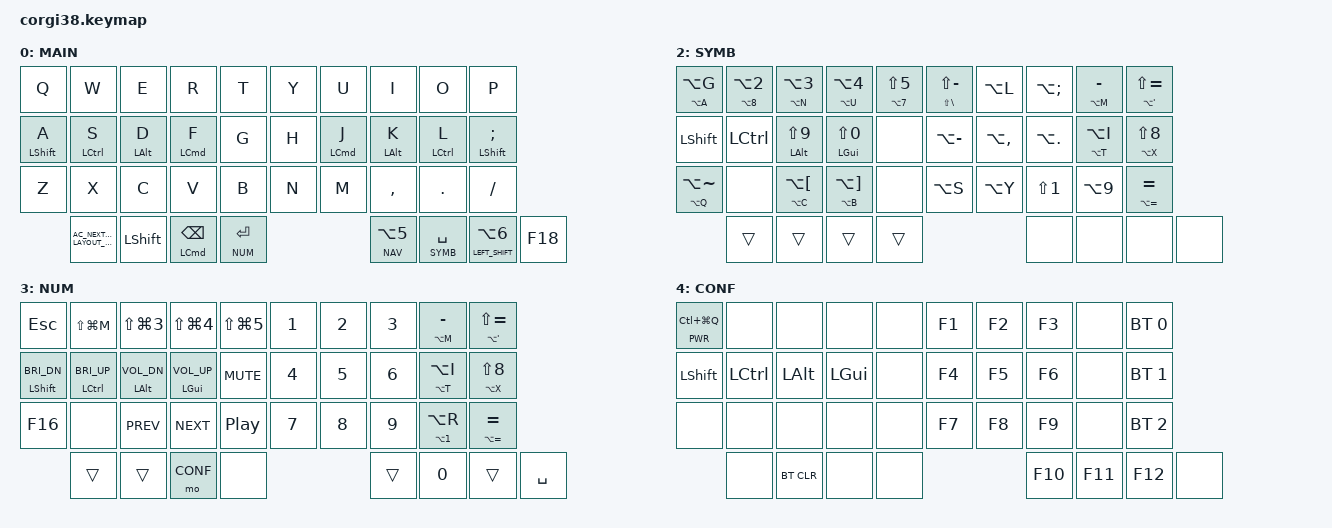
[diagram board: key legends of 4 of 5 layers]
// This keymap is designed for macOS

#include <behaviors.dtsi>
#include <dt-bindings/zmk/keys.h>
#include <dt-bindings/zmk/bt.h>

// LAYERS
#define MAIN  0
#define NAV   1
#define SYMB  2
#define NUM   3
#define CONF  4

#define WDL   &kp LA(BSPC)           //delete a word


&mt {
    tapping-term-ms = <200>;
};

/ {
  combos {
    compatible = "zmk,combos";

    //Caps Word Behavior, tap SW11 and SW20 at the same time
    combo_space {
    timeout-ms = <200>;
    key-positions = <32 33>;
    bindings = <&kp SPACE>;
        };

    //Tab Behavior, tap SW36 and SW37 at the same time
    combo_tab {
    timeout-ms = <200>;
    key-positions = <34 35>;
    bindings = <&kp TAB>;
        };

    //word delete Behavior, 
    combo_word_delete {
    timeout-ms = <150>;
    key-positions = <31 32>;
    bindings = <WDL>;
        };

    //combo_capslock {
    //timeout-ms = <150>;
    //key-positions = <10 19>;
    //bindings = <&caps_word>;
       // };

    //Change imput language, tap SW34 and SW35 at the same time
    combo_lang {
    timeout-ms = <300>;
    key-positions = <33 34>;
    bindings = <&lang>;
              };
    };

  behaviors {

  //macOS imput language shortcut: CMD+Space on Tap, Alt+Opt+Space on 2 taps (Tap-Dance Behavior) 
  lang: lang_lang {
    compatible = "zmk,behavior-tap-dance";
    #binding-cells = <0>;
    tapping-term-ms = <200>;
    bindings = <&kp LG(SPACE)>, <&kp LC(LA(SPACE))>;
        };      

  //Home Mods config for the MAIN layer  
  hm: hold_tap_mods {
    compatible = "zmk,behavior-hold-tap";
    #binding-cells = <2>;
    tapping_term_ms = <160>;
    require-prior-idle-ms = <125>;
    flavor = "tap-preferred";
    bindings = <&kp>, <&kp>;
};

  //Home Mods for shifts  
  sh: hold_tap_shifts {
    compatible = "zmk,behavior-hold-tap";
    #binding-cells = <2>;
    tapping_term_ms = <200>;
    flavor = "hold-preferred";
    bindings = <&kp>, <&kp>;
};

  //Hold-taps config for thumb claster (layer switching)
  hl: hold_tap_layers {
    compatible = "zmk,behavior-hold-tap";
    #binding-cells = <2>;
    tapping_term_ms = <180>;
    flavor = "hold-preferred";
    bindings = <&mo>, <&kp>;
};

  //Hold-taps config for thumb space
  sp: hold_tap_sp {
    compatible = "zmk,behavior-hold-tap";
    #binding-cells = <2>;
    tapping_term_ms = <130>;
    flavor = "hold-preferred";
    require-prior-idle-ms = <125>;
    bindings = <&mo>, <&kp>;
};

  };

    keymap {
        compatible = "zmk,keymap";

        // | SW1  | SW2  | SW3  | SW4  | SW5  |         | SW6  | SW7  | SW8  | SW9  | SW10 |
        // | SW11 | SW12 | SW13 | SW14 | SW15 |         | SW16 | SW17 | SW18 | SW19 | SW20 |
        // | SW21 | SW22 | SW23 | SW24 | SW25 |         | SW26 | SW27 | SW28 | SW29 | SW30 |
        //        | SW31 | SW32 | SW33 | SW34 |         | SW35 | SW36 | SW37 | SW38 |

        //MAIN Layer

        //Home Mods and letters for the LEFT half
        #define HM_A          &hm LEFT_SHIFT A           //SW11
        #define HM_S          &hm LEFT_CONTROL S         //SW12
        #define HM_D          &hm LEFT_ALT D             //SW13
        #define HM_F          &hm LCMD F                 //SW14
        
        //Home Mods for the RIGHT half 
        #define HM_J          &hm LCMD J                 //SW17
        #define HM_K          &hm LEFT_ALT K             //SW18
        #define HM_L          &hm LEFT_CONTROL L         //SW19
        #define HM_SEMI       &hm LEFT_SHIFT SEMI        //SW20
                                                         //SW30: &lang (macOS lang behavior)


        //Left Thumbs
        #define SPECE_SHIFT   &sh LEFT_SHIFT  SPACE      //SW31: ESC on Tap
                                                         //SW32: Space on Tap
        #define BSPC_CMD      &mt LCMD BSPC              //SW33: CMD on hold, Backspace on Tap
        #define NUM_ENTER     &hl NUM   ENTER            //SW34: NUMB layer on hold, ENTER on Tap

        //Right Thumbs
        #define NAV_COMMA     &hl NAV   LA(N5)           //SW35: NAV layer onf hold, COMMA on Tap
        #define SYMB_SPACE    &sp SYMB  SPACE            //SW36: Symbol layer on hold, Space on Tap
        #define MY_DOT        &sp LEFT_SHIFT   LA(N6)    //SW37: Custom DOT on tap
                                                         //F14 on Tap

        default_layer {
            display-name = "MAIN";
              bindings = <
                &kp Q       &kp W           &kp E          &kp R           &kp T                     &kp Y         &kp U         &kp I          &kp O         &kp P      
                HM_A        HM_S            HM_D           HM_F            &kp G                     &kp H         HM_J          HM_K           HM_L          HM_SEMI  
                &kp Z       &kp X           &kp C          &kp V           &kp B                     &kp N         &kp M         &kp COMMA      &kp DOT       &kp SLASH
                            &kp C_AC_NEXT_KEYBOARD_LAYOUT_SELECT       &kp LSHFT      BSPC_CMD        NUM_ENTER                 NAV_COMMA     SYMB_SPACE    MY_DOT         &kp F18 
                                  >;

                 };   

        //Nav layer
        // | SW1  | SW2  | SW3  | SW4  | SW5  |         | SW6  | SW7  | SW8  | SW9  | SW10 |
        // | SW11 | SW12 | SW13 | SW14 | SW15 |         | SW16 | SW17 | SW18 | SW19 | SW20 |
        // | SW21 | SW22 | SW23 | SW24 | SW25 |         | SW26 | SW27 | SW28 | SW29 | SW30 |
        //        | SW31 | SW32 | SW33 | SW34 |         | SW35 | SW36 | SW37 | SW38 |

        //RAW1
                                                          //SW1: &none 
                                                          //SW2: &none                                                  
                                                          //SW3: &none                                                      
                                                          //SW4: &none
        #define DRSS_E         &mt LS(GRAVE) GRAVE        //SW5: E with diaeresis (Ë), shifted on hold

        #define ZOOM_OUT       &kp LG(MINUS)              //SW6: CMD- shortcut 
        #define ZOOM_IN        &kp LG(EQUAL)              //SW7: CMD+ shortcut 
        #define ARROW_UP       &kp UP                     //SW8: arrow up
                                                          //SW9: &none 
        #define CYR_X          &mt LS(LBKT) LBKT          //SW10: Cyrillic x, and X on hold

        //RAW2
                                                          //SW11: LSHFT on tap
                                                          //SW12: LCTRL on tap 
                                                          //SW13: LALT on tap
                                                          //SW14: LGUI on tap
                                                          //SW15: &none 
 
                                                          //SW16: TAB on Tap 
        #define ARROW_LEFT     &kp LEFT                   //SW17: arrow left
        #define ARROW_DOWN     &kp DOWN                   //SW18: arrow down
        #define ARROW_RIGHT    &kp RIGHT                  //SW19: arrow right
        #define CYR_E          &mt LS(APOS) APOS          //SW20: Cyrillic э, and Э on hold


        //RAW3
                                                          //SW21: &none 
                                                          //SW22: &none                                                  
                                                          //SW23: &none                                                      
                                                          //SW24: &none
                                                          //SW25: &none

                                                          //SW26: &none
        #define CYR_HS         &mt LS(RBKT) RBKT          //SW27: Cyrillic ъ, and Ъ on hold (hard sign)
                                                          //SW28: &none                                                      
                                                          //SW29: &none
                                                          //SW30: &none
        #define S_QMARK         &mt LA(F) LA(N9)          //SW27: ? on tap, ¿ on hold 
        #define S_EXCLAM        &mt LA(D) LS(N1)          //SW28: ! on tap, ¡ on hold

        //Left Thumbs
                                                         //SW31: ESC on Tap
                                                         //SW32: Space on Tap
                                                         //SW33: CMD on hold, Backspace on Tap
                                                         //SW34: NUMB layer on hold, ENTER on Tap

        //Right Thumbs
                                                         //SW35: &none
                                                         //SW36: &none

        

        navigation_layer {
            display-name = "NAV";
              bindings = <
                &none          &none           &none          &none           DRSS_E                   ZOOM_OUT      ZOOM_IN         ARROW_UP        &none            CYR_X      
                &kp LSHFT      &kp LCTRL       &kp LALT       &kp LGUI        &kp F16                  &kp TAB       ARROW_LEFT      ARROW_DOWN      ARROW_RIGHT      CYR_E
                &none          &none           &none          &none           &none                    &none         &none           &none           &none
                               &trans          &trans         &trans          &trans                   &none         &none           &none           &none
                                  >; 
                      };


        //SYMB layer

        // | SW1  | SW2  | SW3  | SW4  | SW5  |         | SW6  | SW7  | SW8  | SW9  | SW10 |
        // | SW11 | SW12 | SW13 | SW14 | SW15 |         | SW16 | SW17 | SW18 | SW19 | SW20 |
        // | SW21 | SW22 | SW23 | SW24 | SW25 |         | SW26 | SW27 | SW28 | SW29 | SW30 |
        //        | SW31 | SW32 | SW33 | SW34 |         | SW35 | SW36 | SW37 | SW38 |

        //ROW 1      
        #define S_TILDE         &mt LA(A) LA(G)          //SW1: ~ on tap, ≈ on hold
        #define S_AT            &mt LA(N8) LA(N2)        //SW2: @ on tap, ∞ on hold
        #define S_HASH          &mt LA(N) LA(N3)         //SW3: # on tap, № on hold
        #define S_DOLLAR        &mt LA(U) LA(N4)         //SW4: ₴ on tap, $ on hold
        #define S_PERCENT       &mt LA(N7) LS(N5)        //SW5: % on tap, & on hold

        #define S_UNDER         &mt LS(BSLH) LS(MINUS)   //SW6: _ on tap, | on hold
        #define S_LESSTHAN      &kp LA(L)                //SW7: < on tap
        #define S_GREATERTHAN   &kp LA(SEMI)             //SW8: > on tap
        #define S_MINUS         &mt LA(M) MINUS          //SW9: - on tap, − on hold
        #define S_PLUS          &mt LA(APOS) LS(EQUAL)   //SW10: + on tap, ± on hold

        //ROW 2
        #define HM_LSHIFT       &kp LSHFT                //SW11: Left Shift on tap
        #define HM_LCTRL        &kp LCTRL                //SW12: Left Ctrl on tap
        #define HM_LALT_LPAR    &hm LALT LS(N9)          //SW13: ( on tap, Left Alt on hold
        #define HM_LCMD_RPAR    &hm LGUI LS(N0)          //SW14: ) on tap, Left CMD on hold
                                                         //SW15: &none

        #define S_DASH          &kp LA(MINUS)            //SW16: —(long) on tap, ‒(middle) on hold
        #define UKR_LPAW        &kp LA(COMMA)            //SW17: « on tap
        #define UKR_RPAW        &kp LA(DOT)              //SW18: » on tap
        #define S_SLASH         &mt LA(T) LA(I)          //SW19: / on tap, \ on hold
        #define S_STAR          &mt LA(X) LS(N8)         //SW20: * on tap, × on hold

        //ROW 3
        #define ACCENT_CARET    &mt LA(Q) LA(TILDE)      //SW21: ` on tap, ^ on hold
                                                         //SW22: &none
        #define LBRKT_LBRACE    &mt LA(C) LA(LBKT)       //SW23: [ on tap, { on hold
        #define RBRKT_RBRACE    &mt LA(B) LA(RBKT)       //SW24: ] on tap, } on hold
                                                         //SW25: &none

        #define SMCOL_COL       &mt LA(Y) LA(S)          //SW26: : on tap, ; on hold
        #define APOSTR_QUOTE    &mt LA(N1) LA(R)         //SW29: ' on tap, " on hold
        #define S_EQUAL         &mt LA(EQUAL) EQUAL      //SW30: = on tap, ≠ on hold


        //Left Thumbs
                                                         //SW31: ESC on Tap
                                                         //SW32: Space on Tap
                                                         //SW33: CMD on hold, Backspace on Tap
                                                         //SW34: NUMB layer on hold, ENTER on Tap

        //Right Thumbs
                                                         //SW35: &none
                                                         //SW36: &none
                                                         //SW37: &none
                                                         //SW38: &none



        symbols_layer {
            display-name = "SYMB";
              bindings = <
                S_TILDE         S_AT            S_HASH          S_DOLLAR        S_PERCENT                        S_UNDER       S_LESSTHAN      S_GREATERTHAN    S_MINUS         S_PLUS      
                HM_LSHIFT       HM_LCTRL        HM_LALT_LPAR    HM_LCMD_RPAR    &none                            S_DASH        UKR_LPAW        UKR_RPAW         S_SLASH         S_STAR  
                ACCENT_CARET    &none           LBRKT_LBRACE    RBRKT_RBRACE    &none                            &kp LA(S)     &kp LA(Y)       &kp LS(N1)       &kp LA(N9)      S_EQUAL
                                &trans          &trans          &trans          &trans                           &none         &none           &none            &none
                                  >;

                      };


        // | SW1  | SW2  | SW3  | SW4  | SW5  |         | SW6  | SW7  | SW8  | SW9  | SW10 |
        // | SW11 | SW12 | SW13 | SW14 | SW15 |         | SW16 | SW17 | SW18 | SW19 | SW20 |
        // | SW21 | SW22 | SW23 | SW24 | SW25 |         | SW26 | SW27 | SW28 | SW29 | SW30 |
        //        | SW31 | SW32 | SW33 | SW34 |         | SW35 | SW36 | SW37 | SW38 |

        //ROW 1  
                                                         //SW1: ESC on tap
                                                         //SW2: &none
        #define S_3             &kp LS(LG(N3))           //SW3: Shift+Cmd+3 on tap (screenshot)   C_BRI_DN: brightness DOWN
        #define S_4             &kp LS(LG(N4))           //SW4: Shift+Cmd+4 on tap (screenshot) C_BRI_DN: brightness UP
        #define S_5             &kp LS(LG(N5))           //SW5: Shift+Cmd+5 on tap (screenshot)

                                                         //SW6: 1 on tap
                                                         //SW7: 2 on tap
                                                         //SW8: 3 on tap
                                                         //SW9: - on tap, − on hold
                                                         //SW10: + on tap, ± on hold   

        //ROW 2
        #define LSHIFT_BRI_DN   &hm LSHIFT C_BRI_DN      //SW11: brightness DOWN, Left Shoft on hold
        #define LCTRL_BRI_UP    &hm LCTRL C_BRI_UP       //SW12: brightness UP, Left Ctrl on hold
        #define HM_LALT_VLD     &hm LALT C_VOL_DN        //SW13: Volume Down on tap, Left Alt on hold
        #define HM_LCMD_VLU     &hm LGUI C_VOL_UP        //SW14: Volume Up on tap, Left CMD on hold
                                                         //SW15: Mute on tap

                                                         //SW16: 4 on tap
                                                         //SW17: 5 on tap
                                                         //SW18: 6 on tap
                                                         //SW19: / on tap, \ on hold
                                                         //SW20: * on tap, × on hold

        //ROW 3
                                                         //SW21: CapsLock on tap
                                                         //SW22: &none
                                                         //SW23: Previus on tap
                                                         //SW24: Next on tap
                                                         //SW25: Play/Pause on tap

                                                         //SW26: 7 on tap
                                                         //SW27: 8 on tap 
                                                         //SW28: 9 on tap
                                                         //SW29: ' on tap, " on hold
                                                         //SW30: = on tap, ≠ on hold

        //Left Thumbs
                                                         //SW31: ESC on Tap
                                                         //SW32: &none
                                                         //SW33: CONF layer
                                                         //SW34: &none
        //Right Thumb
                                                         //SW35: Comma on tap 
                                                         //SW36: 0 on tap
                                                         //SW37: DOT on tap
                                                         //SW38: &none

        numbers_layer {
            display-name = "NUM";
              bindings = <
                &kp ESC          &kp LS(LG(M))   S_3             S_4             S_5                              &kp N1        &kp N2      &kp N3           S_MINUS         S_PLUS      
                LSHIFT_BRI_DN    LCTRL_BRI_UP    HM_LALT_VLD     HM_LCMD_VLU     &kp K_MUTE                       &kp N4        &kp N5      &kp N6           S_SLASH         S_STAR  
                &kp F16          &none           &kp C_PREV      &kp C_NEXT      &kp C_PP                         &kp N7        &kp N8      &kp N9           APOSTR_QUOTE    S_EQUAL
                                 &trans          &trans          &mo CONF        &none                             &trans        &kp N0      &trans           &kp SPACE
                      >;           

                      };                 


        //CONF layer

        // | SW1  | SW2  | SW3  | SW4  | SW5  |         | SW6  | SW7  | SW8  | SW9  | SW10 |
        // | SW11 | SW12 | SW13 | SW14 | SW15 |         | SW16 | SW17 | SW18 | SW19 | SW20 |
        // | SW21 | SW22 | SW23 | SW24 | SW25 |         | SW26 | SW27 | SW28 | SW29 | SW30 |
        //        | SW31 | SW32 | SW33 | SW34 |         | SW35 | SW36 | SW37 | SW38 |

        //ROW 1  
        #define POWER_LOCK      &mt C_PWR LC(LG(Q))      //SW1: Lock on tap, Power on hold
                                                         //SW2: &none
                                                         //SW3: &none
                                                         //SW4: &none
                                                         //SW2: &none

                                                         //SW6: F1 on tap
                                                         //SW7: F2 on tap
                                                         //SW8: F3 on tap
                                                         //SW9: &none
                                                         //SW10: Select the main (0) bt-rofile, on tap

        //ROW 2
                                                         //SW11: Left Shift on tap
                                                         //SW12: Left Ctrl on tap
                                                         //SW13: Left Alt on tap
                                                         //SW14: Left CMD on tap
                                                         //SW15: Clear bond information between the keyboard and host for the selected profile

                                                         //SW16: F4 on tap
                                                         //SW17: F5 on tap
                                                         //SW18: F6 on tap
                                                         //SW19: &none
                                                         //SW20: Select the 2st (1) bt-rofile, on tap

        //ROW 3
                                                         //SW21: &none
                                                         //SW22: &none
                                                         //SW23: &none
                                                         //SW24: &none
                                                         //SW25: &none

                                                         //SW26: F7 on tap
                                                         //SW27: F8 on tap
                                                         //SW28: F9 on tap 
                                                         //SW29: &none
                                                         //SW30: Select the 3st (2) bt-rofile, on tap

        //Left Thumbs
                                                         //SW31: &none
                                                         //SW32: &none
                                                         //SW33: &none
                                                         //SW34: &none
        //Right Thumb
                                                         //SW35: F10 on tap 
                                                         //SW36: F11 on tap 
                                                         //SW37: F12 on tap 
                                                         //SW38: &none



        config_layer {
            display-name = "CONF";
              bindings = <
                POWER_LOCK      &none           &none           &none           &none                            &kp F1          &kp F2           &kp F3            &none           &bt BT_SEL 0      
                &kp LSHFT       &kp LCTRL       &kp LALT        &kp LGUI        &none                            &kp F4          &kp F5           &kp F6            &none           &bt BT_SEL 1  
                &none           &none           &none           &none           &none                            &kp F7          &kp F8           &kp F9            &none           &bt BT_SEL 2
                                &none           &bt BT_CLR      &none           &none                            &kp F10         &kp F11          &kp F12           &none
                      >;

                      };     



    };
};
